VERSION ""

NS_ :

BS_:

BU_: BMS Charger

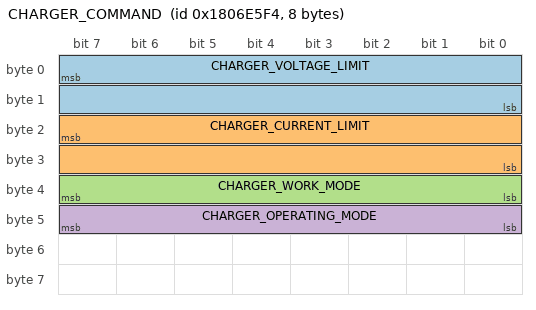
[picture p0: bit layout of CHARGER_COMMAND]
BO_ 403105268 CHARGER_COMMAND: 8 BMS
 SG_ CHARGER_VOLTAGE_LIMIT : 7|16@0+ (0.1,0) [0|680] "V" Vector__XXX
 SG_ CHARGER_CURRENT_LIMIT : 23|16@0+ (0.1,0) [0|14] "A" Vector__XXX
 SG_ CHARGER_WORK_MODE : 39|8@0+ (1,0) [0|2] "Enum" Vector__XXX
 SG_ CHARGER_OPERATING_MODE : 47|8@0+ (1,0) [0|0] "Enum" Vector__XXX

BO_ 419385573 CHARGER_RESPONSE: 8 Charger
 SG_ CHARGE_VOLTGE_OUTPUT : 7|16@0+ (0.1,0) [0|680] "V" Vector__XXX
 SG_ CHARGER_CURRENT_OUTPUT : 23|16@0+ (0.1,0) [0|14] "A" Vector__XXX
 SG_ CHARGER_HARDWARE_PROTECTION : 32|1@0+ (1,0) [0|1] "Bool" Vector__XXX
 SG_ CHARGER_TEMPERATURE_PROTECTION : 33|1@0+ (1,0) [0|1] "Bool" Vector__XXX
 SG_ CHARGER_INPUT_VOLTAGE_STATUS : 35|2@0+ (1,0) [0|1] "Bool" Vector__XXX
 SG_ CHARGER_OUTPUT_UNDERVOLTAGE : 36|1@0+ (1,0) [0|1] "Bool" Vector__XXX
 SG_ CHARGER_OUTPUT_OVERVOLTAGE : 37|1@0+ (1,0) [0|1] "Bool" Vector__XXX
 SG_ CHARGE__OUTPUT_OVERCURRENT : 38|1@0+ (1,0) [0|1] "Bool" Vector__XXX
 SG_ CHARGER_OUTPUT_SHORT_CIRCUIT : 39|1@0+ (1,0) [0|1] "Bool" Vector__XXX
 SG_ CHARGER_COMMAND_FAULT : 40|1@0+ (1,0) [0|1] "Bool" Vector__XXX
 SG_ CHARGER_WORK_STATUS : 42|2@0+ (1,0) [0|3] "Enum" Vector__XXX
 SG_ CHARGER_INITIALIZED : 43|1@0+ (1,0) [0|1] "Bool" Vector__XXX
 SG_ CHARGER_FAN_ENABLED : 44|1@0+ (1,0) [0|1] "Bool" Vector__XXX
 SG_ CHARGER_COOLING_PUMP_ENABLED : 45|1@0+ (1,0) [0|1] "Bool" Vector__XXX
 SG_ CHARGER_CC_STATUS : 49|2@0+ (1,0) [0|3] "Enum" Vector__XXX
 SG_ CHARGER_CP_STATUS : 50|1@0+ (1,0) [0|1] "Bool" Vector__XXX
 SG_ CHARGER_SOCKET_OVERTEMPERATURE : 51|1@0+ (1,0) [0|1] "Bool" Vector__XXX
 SG_ CHARGER_ELECTRONIC_LOCK : 54|3@0+ (1,0) [0|4] "Enum" Vector__XXX
 SG_ CHARGER_S2_SWITCH_CONTROL : 55|1@0+ (1,0) [0|1] "Bool" Vector__XXX
 SG_ CHARGER_TEMPERATURE : 63|8@0+ (1,-40) [-40|205] "C" Vector__XXX

BA_DEF_  "BusType" STRING ;
BA_DEF_DEF_  "BusType" "CAN";

CM_ SG_ 1012 CHARGER_OPERATING_MODE "Must be 0.";
